# RL6845_IP_SVD register map
Vendor: Realtek
Registers are 32-bit, read-write, reset 0x0 unless marked. A register's access mark holds for its fields unless they carry their own. Offsets are from the block's base; [hi:lo] are bit positions.

## auxc
Base 0x41008440
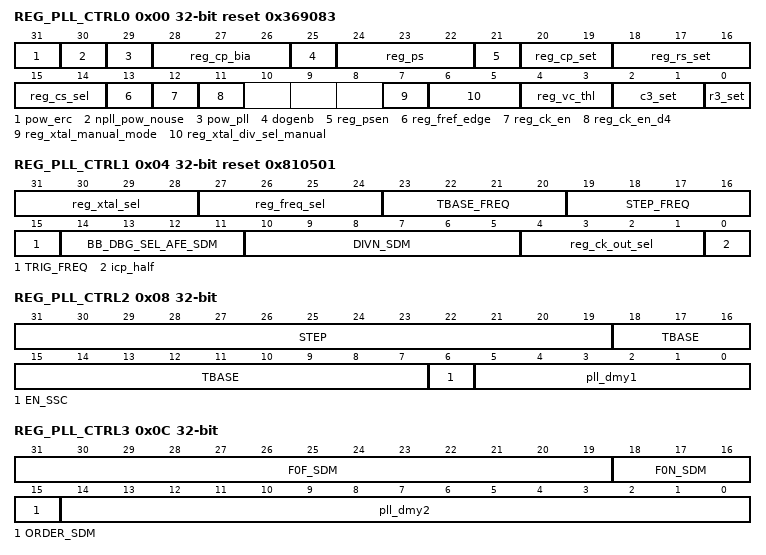
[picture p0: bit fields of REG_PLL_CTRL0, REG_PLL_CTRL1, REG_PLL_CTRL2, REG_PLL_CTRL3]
0x00 REG_PLL_CTRL0 reset 0x369083
  [31] pow_erc — erc enable. 0 -> 1
  [30] npll_pow_nouse — no use:input divider enable (need pwl signal) 0 -> 1
  [29] pow_pll — (need pwl signal) 0 -> 1
  [28:26] reg_cp_bia — charge pump current selection . Default=10uA CP current select : 000: Icp=10uA, 001: Icp=15uA, 010: Icp=20uA, 011: Icp=25uA; 100: Icp=30uA, 101: Icp=35uA, 110: Icp=40uA, 111: Icp=450uA;
  [25] dogenb — 0: watch dog on, 1: watch dog off
  [24:22] reg_ps
  [21] reg_psen — phase selector enable
  [20:19] reg_cp_set — Cp selection. Default=5p 00: Cp=4p, 01: Cp=5p, 10: Cp=6p, 11: Cp=7p XTAL=40MHz : 10 ,Cp=6p XTAL=26MHz : 01 ,Cp=5p
  [18:16] reg_rs_set — Rs selection. Default=4k 000: Rs=15k, 001: Rs=13k, 010: Rs=11k, 011: Rs=9k, 100: Rs=7k, 101: Rs=5k, 110: Rs=3k, 111: Rs=1k; XTAL=40MHz : 110 ,Rs=3k XTAL=26MHz : 101 ,Rs=5K
  [15:14] reg_cs_sel — Cs selection. Default=70p 00: Cs=40p, 01: Cs=50p, 10: Cs=60p, 11: Cs=70p XTAL=40MHz : 11 , Cs=70p XTAL=26MHz : 11 , Cs=70p
  [13] reg_fref_edge — 0:fref, 1:frefb
  [12] reg_ck_en — output clk enable
  [11] reg_ck_en_d4 — output clk div 4 enable
  [7] reg_xtal_manual_mode — reg_xtal_maunal_mode. Default=0 0: reg_xtal_sel<3:0> is controlled by REG, xtal_div_sel is controlled by mapping table. 1: reg_xtal_sel<3:0>=4'b1111, xtal_div_sel is controlled by reg_xtal_div_sel_maunal<1:0>
  [6:5] reg_xtal_div_sel_manual — input divider selection in xtal maunal mode. Default=00 00=/1, 10=/2, 11=/4
  [4:3] reg_vc_thl — VC voltage, Default=00 00: VC=1/4Vdd, 01: VC=1/2Vdd, 10=3/4Vdd, 11: VC=Vdd
  [2:1] c3_set — C3 selection. Default=1p 00: 0.5p, 01: 1p, 10: Cs=1.5p, 11: 2p
  [0] r3_set — Rs selection. Default=1k 0: 0 Ohm, 1: 1k Ohm
0x04 REG_PLL_CTRL1 reset 0x810501
  [31:28] reg_xtal_sel — xtal selection, Default=40MHz 0000= 40MHz, 0101= 26MHz,
  [27:24] reg_freq_sel — no use :output clk selection, Default=400MHz 0000= 400MHz, 0001= X, 0010= X, 0011= X, 0100= 216MHz, 0101=196.608MHz, 0110=192MHz, 0111= 180.632MHz, 1000= 148.5MHz,1001= X, 1010= X, 1011= X, 1100= X, 1101= X, 1110= X, 1111= 500MHz
  [23:20] TBASE_FREQ — now is empty
  [19:16] STEP_FREQ — step size selection for switching freq. 0000: 2^5 0001: 2^6 0010: 2^7 0011: 2^8 0100: 2^9 0101: 2^10 0110: 2^11 0111: 2^12
  [15] TRIG_FREQ — freq. step up or step down enable
  [14:11] BB_DBG_SEL_AFE_SDM
  [10:5] DIVN_SDM — Default 320MHz: 000110 400MHz: 001000 600MHz: 001101
  [4:1] reg_ck_out_sel — output divider selection. Default=0000(/1) 0000=/1, 1000=/2, 1100=/4, 1110=/8, 1111=/16 300~330MHz PLL output clock, output divider selection. 1000=/2 Ex : 600MHz/2=300MHz 330~660MHz PLL output clock, output divider selection. 0000=/1 Ex : 660MHz/1=660MHz Spec:/2(mandatory
  [0] icp_half — charge pump current half or not 0: no half 1: half
0x08 REG_PLL_CTRL2
  [31:19] STEP — ssc step size selection.
  [18:7] TBASE — ssc freq selection
  [6] EN_SSC — ssc enable. Default=0
  [5:0] pll_dmy1 — HW used only , these are for reserved
0x0C REG_PLL_CTRL3
  [31:19] F0F_SDM — Default 660MHz: 0000000000000 330MHz: 0000000000000 600MHz: 0000000000000 660MHz: 0000000000000
  [18:16] F0N_SDM — Default 660MHz: 100 330MHz: 010 600MHz: 000 660MHz: 100
  [15] ORDER_SDM — SDM order
  [14:0] pll_dmy2 — HW used only , these are for reserved
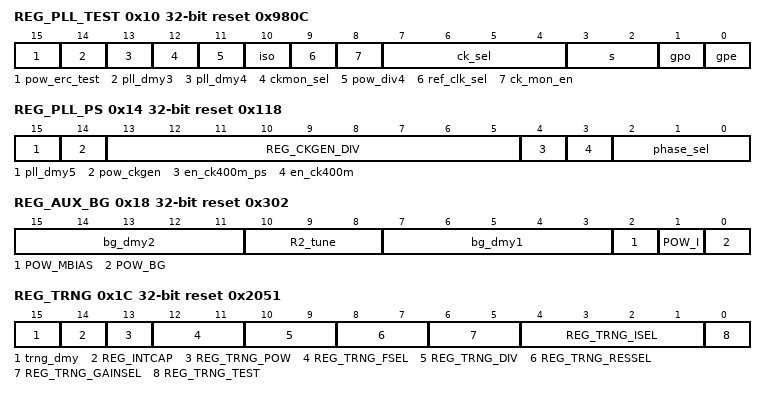
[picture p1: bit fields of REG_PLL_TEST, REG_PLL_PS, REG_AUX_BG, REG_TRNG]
0x10 REG_PLL_TEST reset 0x980C
  [15] pow_erc_test — 1 for enable test, 0 for disable
  [14] pll_dmy3 — dummy
  [13] pll_dmy4 — 0 for ckmon div 4 , 1 for ckmon div 8
  [12] ckmon_sel — 0 for CKMON, 1 for CKMOND div by 4
  [11] pow_div4 — 1 for ckmon div 4 , 0 for disable div 4
  [10] iso — 1 for ISO ck_fref/ck_frefb
  [9] ref_clk_sel — xtal clk from 0 special route 1 APR
  [8] ck_mon_en — ckmon enable
  [7:4] ck_sel — ckmon clk sel 1111:TL 1110:TL 1101:CK_CPUD4_I 1100:CK_400M_CPU_I 1011:TL 1010:TL 1001:TL 1000:READY_CPU_I 0111:ck_frefi_peri(xtal) 0110:TL 0101:TL 0100:TL 0011:TL 0010:TL 0001:TL 0000:TL
  [3:2] s — AGPIO driving sel
  [1] gpo — AGPIO output enable
  [0] gpe — AGPIO enable
0x14 REG_PLL_PS reset 0x118
  [15] pll_dmy5 — HW used only , these are for reserved
  [14] pow_ckgen — pow of ckgen
  [13:5] REG_CKGEN_DIV — DIV9B , N=DIV<8:0>+2
  [4] en_ck400m_ps — enable shifted clk source for flash
  [3] en_ck400m — ck400m is PLL VCO freq (300M~600M)
  [2:0] phase_sel — AGPIO driving sel
0x18 REG_AUX_BG reset 0x302
  [15:11] bg_dmy2 — HW used only , these are for reserved
  [10:8] R2_tune — Add 20k per step fine tune BG
  [7:3] bg_dmy1 — HW used only , these are for reserved
  [2] POW_MBIAS — power on mbias
  [1] POW_I — power on BG current
  [0] POW_BG — power on BG
0x1C REG_TRNG reset 0x2051
  [15] trng_dmy — dummy
  [14] REG_INTCAP — OPA_INT cap<9:4> control
  [13] REG_TRNG_POW — ROSC poewr on control 1:power on 0:power off
  [12:11] REG_TRNG_FSEL — ROSC frequency range control
  [10:9] REG_TRNG_DIV — ROSC output clock divider control 00: divide by 1 01: divide by 2 10: divide by 3 11: divide by 4
  [8:7] REG_TRNG_RESSEL — ROSC noise resistor control 00: 562k 01: 749k 10: 936k 11: 1123k
  [6:5] REG_TRNG_GAINSEL — ROSC noise gain control 00: 32dB 01: 35dB 10: 38dB 11: 40dB
  [4:1] REG_TRNG_ISEL — ROSC frequency control data input
  [0] REG_TRNG_TEST — Analog test signal enable control 0: off 1: on
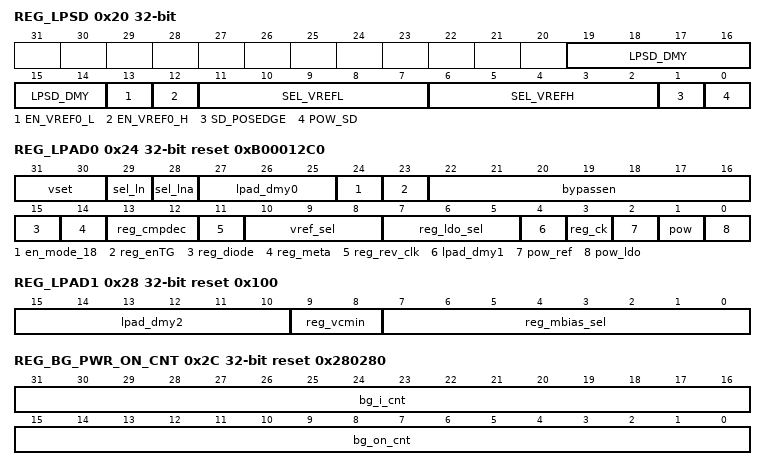
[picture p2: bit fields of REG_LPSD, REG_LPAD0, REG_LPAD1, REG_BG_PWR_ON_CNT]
0x20 REG_LPSD access per field
  [19:14] LPSD_DMY rw — dummy
  [13] EN_VREF0_L rw — set VREFL to 0
  [12] EN_VREF0_H rw — set VREFH to 0
  [11:7] SEL_VREFL ro — adjust VREFL
  [6:2] SEL_VREFH ro — adjust VREFH
  [1] SD_POSEDGE rw — 1: vin>vref output high
  [0] POW_SD rw — Power on signal detector
0x24 REG_LPAD0 reset 0xB00012C0
  [31:30] vset — 11:1.89V 10:1.80V 01:1.71V 00:1.62V
  [29] sel_ln — 1: comparator low noise for LSB 6bit
  [28] sel_lna — 1: comparator low noise for ALL bit
  [27:25] lpad_dmy0 — dummy
  [24] en_mode_18 — 1: enable 1.8V mode
  [23] reg_enTG — 1: enable transmission gate
  [22:16] bypassen — 1:bypass mode, 0: divide mode
  [15] reg_diode — 1: enable diode
  [14] reg_meta — 1: enable meta detect
  [13:12] reg_cmpdec — meta detect time 00: short
  [11] reg_rev_clk — 1: rever ck_data
  [10:8] vref_sel — 000:0.800V 001:0.825V 010:0.850V 011:0.875V 100:0.900V 101:0.950V 110:1.000V 111:1.050V
  [7:5] reg_ldo_sel — 000:0.800V 001:0.825V 010:0.850V 011:0.875V 100:0.900V 101:0.950V 110:1.000V 111:1.050V
  [4] lpad_dmy1 — dummy
  [3] reg_ck — 1: clk from external
  [2] pow_ref — pow adc refgen
  [1] pow — pow adc
  [0] pow_ldo
0x28 REG_LPAD1 access per field reset 0x100
  [15:10] lpad_dmy2 rw — dummy
  [9:8] reg_vcmin rw — 00:0.4625V 01:0.4500V 10:0.4375V 11:0.4250V
  [7:0] reg_mbias_sel ro — 00000000:0uA 00000001:0.25uA 00000010:0.5uA 00000011:0.75uA ..............11111111:63.75uA
0x2C REG_BG_PWR_ON_CNT reset 0x280280
  [31:16] bg_i_cnt, [15:0] bg_on_cnt
0x30 REG_ADC_PWR_ON_CNT reset 0x4B0
  [15:0] adc_pwron_cnt
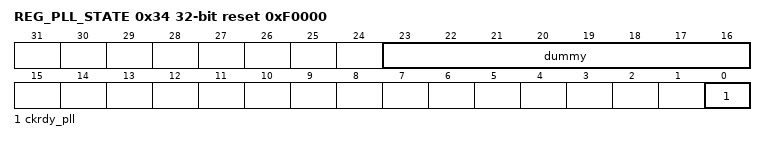
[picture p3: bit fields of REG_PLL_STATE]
0x34 REG_PLL_STATE access per field reset 0xF0000
  [23:16] dummy rw
  [0] ckrdy_pll ro — PLL clock is ready
0x38 REG_DEBUG ro
  [31:0] adbg_aux — dummy
0x3C REG_DUMMY reset 0xF
  [7:0] dummy
